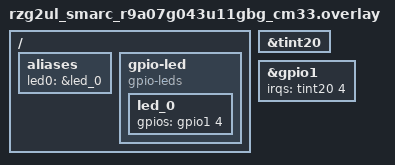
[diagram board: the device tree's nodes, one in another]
/*
 * Copyright (c) 2025 Renesas Electronics Corporation
 * SPDX-License-Identifier: Apache-2.0
 */

/ {
	aliases {
		led0 = &led_0;
	};

	gpio-led {
		compatible = "gpio-leds";

		led_0: led_0 {
			gpios = <&gpio1 4 0>;
		};
	};
};

&tint20 {
	status = "okay";
};

&gpio1 {
	irqs = <&tint20 4>;
	status = "okay";
};
